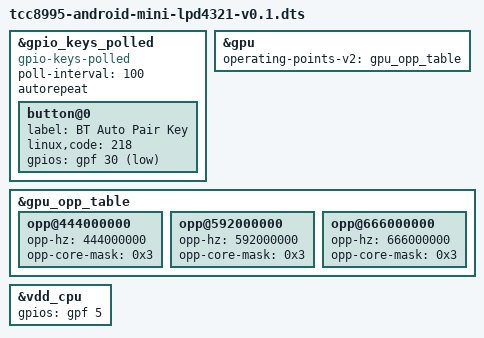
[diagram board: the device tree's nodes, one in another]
// SPDX-License-Identifier: (GPL-2.0+ OR MIT)
/*
 * Device tree for Telechips TCC8990 STB board
 *
 * Copyright (C) 2018 Telechips Inc. - http://www.telechips.com
*/

#ifndef DT_OVERLAY
/dts-v1/;
#endif

#include "tcc8995-android-mini.dtsi"

&gpio_keys_polled {
	compatible = "gpio-keys-polled";
	#address-cells = <1>;
	#size-cells = <0>;
	poll-interval = <100>;
	autorepeat;
	button@0 {
		label = "BT Auto Pair Key";
		linux,code = <218>;
		gpios = <&gpf 30 1>;
	};
};

&gpu {
        operating-points-v2 = <&gpu_opp_table>;
};

&gpu_opp_table {
    opp@444000000 {
	opp-hz = /bits/ 64 <444000000>;
	opp-core-mask = /bits/ 64 <0x3>;
    };
    opp@592000000 {
        opp-hz = /bits/ 64 <592000000>;
        opp-core-mask = /bits/ 64 <0x3>;
    };
    opp@666000000 {
        opp-hz = /bits/ 64 <666000000>;
        opp-core-mask = /bits/ 64 <0x3>;
    };
};

&vdd_cpu {

	gpios = <&gpf 5 0x4>;

};
